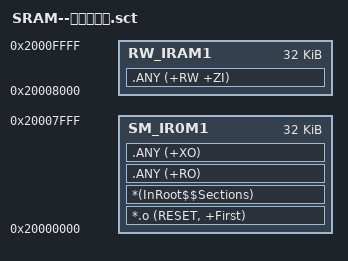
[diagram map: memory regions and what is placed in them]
; *************************************************************
; *** Scatter-Loading Description File generated by uVision ***
; *************************************************************

LR_IRAM1 0x20000000 0x00010000  {    ; load region size_region
  SM_IR0M1 0x20000000 0x00008000  {  ; load address = execution address ;模拟ROM
   *.o (RESET, +First)
   *(InRoot$$Sections)
   .ANY (+RO)
   .ANY (+XO)
  }
  RW_IRAM1 0x20008000 0x0008000  {  ; RW data
   .ANY (+RW +ZI)
  }
}

